AUTOSAR XML (schema 00046)
package /ComponentTypes
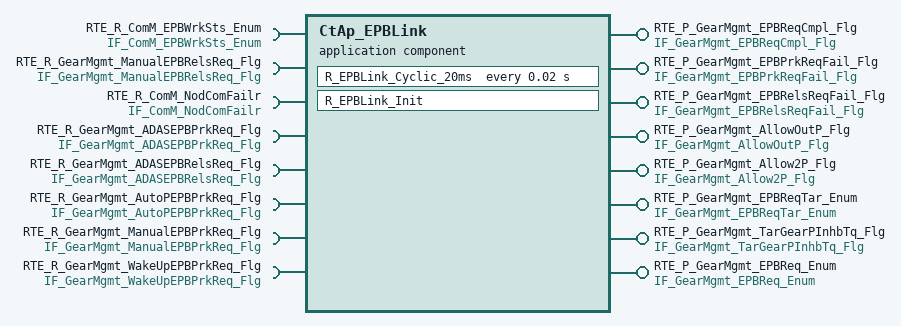
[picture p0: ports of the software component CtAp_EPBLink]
  application sw component type CtAp_EPBLink
    8 x require port:
      RTE_R_ComM_EPBWrkSts_Enum: nonqueued-receiver-com-spec{data-element=tec_ComM_EPBWrkSts_Enum, filter=data-filter-type=ALWAYS, init-value=0}, required-interface=IF_ComM_EPBWrkSts_Enum
      RTE_R_GearMgmt_ManualEPBRelsReq_Flg: nonqueued-receiver-com-spec{data-element=tec_GearMgmt_ManualEPBRelsReq_Flg, filter=data-filter-type=ALWAYS, init-value=0}, required-interface=IF_GearMgmt_ManualEPBRelsReq_Flg
      RTE_R_ComM_NodComFailr: required-interface=IF_ComM_NodComFailr
        required-com-specs:
          data-element=tec_ComM_ACUNodComFailr_Flg, filter=data-filter-type=ALWAYS, init-value=0
          data-element=tec_ComM_SGWNodComFailr_Flg, filter=data-filter-type=ALWAYS, init-value=0
          data-element=tec_ComM_CGWNodComFailr_Flg, filter=data-filter-type=ALWAYS, init-value=0
          data-element=tec_ComM_TCUNodComFailr_Flg, filter=data-filter-type=ALWAYS, init-value=0
          data-element=tec_ComM_BCMNodComFailr_Flg, filter=data-filter-type=ALWAYS, init-value=0
          data-element=tec_ComM_PRNDNodComFailr_Flg, filter=data-filter-type=ALWAYS, init-value=0
          data-element=tec_ComM_IVINodComFailr_Flg, filter=data-filter-type=ALWAYS, init-value=0
          data-element=tec_ComM_DCDCNodComFailr_Flg, filter=data-filter-type=ALWAYS, init-value=0
          data-element=tec_ComM_OBCNodComFailr_Flg, filter=data-filter-type=ALWAYS, init-value=0
          data-element=tec_ComM_CHIBSNodComFailr_Flg, filter=data-filter-type=ALWAYS, init-value=0
          data-element=tec_ComM_MCUNodComFailr_Flg, filter=data-filter-type=ALWAYS, init-value=0
          data-element=tec_ComM_EVCOMNodComFailr_Flg, filter=data-filter-type=ALWAYS, init-value=0
          data-element=tec_ComM_EPTIBSNodComFailr_Flg, filter=data-filter-type=ALWAYS, init-value=0
          data-element=tec_ComM_DCMNodComFailr_Flg, filter=data-filter-type=ALWAYS, init-value=0
          data-element=tec_ComM_BMSNodComFailr_Flg, filter=data-filter-type=ALWAYS, init-value=0
          data-element=tec_ComM_APTCNodComFailr_Flg, filter=data-filter-type=ALWAYS, init-value=0
          data-element=tec_ComM_ADCUNodComFailr_Flg, filter=data-filter-type=ALWAYS, init-value=0
          data-element=tec_ComM_DCMRRNodComFailr_Flg, filter=data-filter-type=ALWAYS, init-value=0
          data-element=tec_ComM_DCMRLNodComFailr_Flg, filter=data-filter-type=ALWAYS, init-value=0
          data-element=tec_ComM_DCMFRNodComFailr_Flg, filter=data-filter-type=ALWAYS, init-value=0
          data-element=tec_ComM_DCMFLNodComFailr_Flg, filter=data-filter-type=ALWAYS, init-value=0
          data-element=tec_ComM_SGWCHNodComFailr_Flg, init-value=0
      RTE_R_GearMgmt_ADASEPBPrkReq_Flg: nonqueued-receiver-com-spec{data-element=tec_GearMgmt_ADASEPBPrkReq_Flg, filter=data-filter-type=ALWAYS, init-value=0}, required-interface=IF_GearMgmt_ADASEPBPrkReq_Flg
      RTE_R_GearMgmt_ADASEPBRelsReq_Flg: nonqueued-receiver-com-spec{data-element=tec_GearMgmt_ADASEPBRelsReq_Flg, filter=data-filter-type=ALWAYS, init-value=0}, required-interface=IF_GearMgmt_ADASEPBRelsReq_Flg
      RTE_R_GearMgmt_AutoPEPBPrkReq_Flg: nonqueued-receiver-com-spec{data-element=tec_GearMgmt_AutoPEPBPrkReq_Flg, filter=data-filter-type=ALWAYS, init-value=0}, required-interface=IF_GearMgmt_AutoPEPBPrkReq_Flg
      RTE_R_GearMgmt_ManualEPBPrkReq_Flg: nonqueued-receiver-com-spec{data-element=tec_GearMgmt_ManualEPBPrkReq_Flg, filter=data-filter-type=ALWAYS, init-value=0}, required-interface=IF_GearMgmt_ManualEPBPrkReq_Flg
      RTE_R_GearMgmt_WakeUpEPBPrkReq_Flg: nonqueued-receiver-com-spec{data-element=tec_GearMgmt_WakeUpEPBPrkReq_Flg, filter=data-filter-type=ALWAYS, init-value=0}, required-interface=IF_GearMgmt_WakeUpEPBPrkReq_Flg
    8 x provide port:
      RTE_P_GearMgmt_EPBReqCmpl_Flg: nonqueued-sender-com-spec{data-element=tec_GearMgmt_EPBReqCmpl_Flg, init-value=0}, provided-interface=IF_GearMgmt_EPBReqCmpl_Flg
      RTE_P_GearMgmt_EPBPrkReqFail_Flg: nonqueued-sender-com-spec{data-element=tec_GearMgmt_EPBPrkReqFail_Flg, init-value=0}, provided-interface=IF_GearMgmt_EPBPrkReqFail_Flg
      RTE_P_GearMgmt_EPBRelsReqFail_Flg: nonqueued-sender-com-spec{data-element=tec_GearMgmt_EPBRelsReqFail_Flg, init-value=0}, provided-interface=IF_GearMgmt_EPBRelsReqFail_Flg
      RTE_P_GearMgmt_AllowOutP_Flg: nonqueued-sender-com-spec{data-element=tec_GearMgmt_AllowOutP_Flg, init-value=0}, provided-interface=IF_GearMgmt_AllowOutP_Flg
      RTE_P_GearMgmt_Allow2P_Flg: nonqueued-sender-com-spec{data-element=tec_GearMgmt_Allow2P_Flg, init-value=0}, provided-interface=IF_GearMgmt_Allow2P_Flg
      RTE_P_GearMgmt_EPBReqTar_Enum: nonqueued-sender-com-spec{data-element=tec_GearMgmt_EPBReqTar_Enum, init-value=0}, provided-interface=IF_GearMgmt_EPBReqTar_Enum
      RTE_P_GearMgmt_TarGearPInhbTq_Flg: nonqueued-sender-com-spec{data-element=tec_GearMgmt_TarGearPInhbTq_Flg, init-value=0}, provided-interface=IF_GearMgmt_TarGearPInhbTq_Flg
      RTE_P_GearMgmt_EPBReq_Enum: nonqueued-sender-com-spec{data-element=tec_GearMgmt_EPBReq_Enum, init-value=0}, provided-interface=IF_GearMgmt_EPBReq_Enum
    behavior CtAp_EPBLink_InternalBehavior
      timing event TMT_R_EPBLink_Cyclic_20ms: start-on-event=R_EPBLink_Cyclic_20ms, period=0.02
      init event CtAp_EPBLink_InitEvent: start-on-event=R_EPBLink_Init
      runnable R_EPBLink_Cyclic_20ms
        data-receive-point-by-arguments:
          8 x access:
            REC_RTE_R_ComM_EPBWrkSts_Enum_tec_ComM_EPBWrkSts_Enum: accessed-variable=RTE_R_ComM_EPBWrkSts_Enum.tec_ComM_EPBWrkSts_Enum
            REC_RTE_R_ComM_NodComFailr_tec_ComM_CHIBSNodComFailr_Flg: accessed-variable=RTE_R_ComM_NodComFailr.tec_ComM_CHIBSNodComFailr_Flg
            REC_RTE_R_GearMgmt_ADASEPBPrkReq_Flg_tec_GearMgmt_ADASEPBPrkReq_Flg: accessed-variable=RTE_R_GearMgmt_ADASEPBPrkReq_Flg.tec_GearMgmt_ADASEPBPrkReq_Flg
            REC_RTE_R_GearMgmt_ADASEPBRelsReq_Flg_tec_GearMgmt_ADASEPBRelsReq_Flg: accessed-variable=RTE_R_GearMgmt_ADASEPBRelsReq_Flg.tec_GearMgmt_ADASEPBRelsReq_Flg
            REC_RTE_R_GearMgmt_AutoPEPBPrkReq_Flg_tec_GearMgmt_AutoPEPBPrkReq_Flg: accessed-variable=RTE_R_GearMgmt_AutoPEPBPrkReq_Flg.tec_GearMgmt_AutoPEPBPrkReq_Flg
            REC_RTE_R_GearMgmt_ManualEPBPrkReq_Flg_tec_GearMgmt_ManualEPBPrkReq_Flg: accessed-variable=RTE_R_GearMgmt_ManualEPBPrkReq_Flg.tec_GearMgmt_ManualEPBPrkReq_Flg
            REC_RTE_R_GearMgmt_ManualEPBRelsReq_Flg_tec_GearMgmt_ManualEPBRelsReq_Flg: accessed-variable=RTE_R_GearMgmt_ManualEPBRelsReq_Flg.tec_GearMgmt_ManualEPBRelsReq_Flg
            REC_RTE_R_GearMgmt_WakeUpEPBPrkReq_Flg_tec_GearMgmt_WakeUpEPBPrkReq_Flg: accessed-variable=RTE_R_GearMgmt_WakeUpEPBPrkReq_Flg.tec_GearMgmt_WakeUpEPBPrkReq_Flg
        data-send-points:
          8 x access:
            SEND_RTE_P_GearMgmt_Allow2P_Flg_tec_GearMgmt_Allow2P_Flg: accessed-variable=RTE_P_GearMgmt_Allow2P_Flg.tec_GearMgmt_Allow2P_Flg
            SEND_RTE_P_GearMgmt_AllowOutP_Flg_tec_GearMgmt_AllowOutP_Flg: accessed-variable=RTE_P_GearMgmt_AllowOutP_Flg.tec_GearMgmt_AllowOutP_Flg
            SEND_RTE_P_GearMgmt_EPBPrkReqFail_Flg_tec_GearMgmt_EPBPrkReqFail_Flg: accessed-variable=RTE_P_GearMgmt_EPBPrkReqFail_Flg.tec_GearMgmt_EPBPrkReqFail_Flg
            SEND_RTE_P_GearMgmt_EPBRelsReqFail_Flg_tec_GearMgmt_EPBRelsReqFail_Flg: accessed-variable=RTE_P_GearMgmt_EPBRelsReqFail_Flg.tec_GearMgmt_EPBRelsReqFail_Flg
            SEND_RTE_P_GearMgmt_EPBReqCmpl_Flg_tec_GearMgmt_EPBReqCmpl_Flg: accessed-variable=RTE_P_GearMgmt_EPBReqCmpl_Flg.tec_GearMgmt_EPBReqCmpl_Flg
            SEND_RTE_P_GearMgmt_EPBReqTar_Enum_tec_GearMgmt_EPBReqTar_Enum: accessed-variable=RTE_P_GearMgmt_EPBReqTar_Enum.tec_GearMgmt_EPBReqTar_Enum
            SEND_RTE_P_GearMgmt_EPBReq_Enum_tec_GearMgmt_EPBReq_Enum: accessed-variable=RTE_P_GearMgmt_EPBReq_Enum.tec_GearMgmt_EPBReq_Enum
            SEND_RTE_P_GearMgmt_TarGearPInhbTq_Flg_tec_GearMgmt_TarGearPInhbTq_Flg: accessed-variable=RTE_P_GearMgmt_TarGearPInhbTq_Flg.tec_GearMgmt_TarGearPInhbTq_Flg
      runnable R_EPBLink_Init
  swc implementation CtAp_EPBLink_Implementation: behavior=CtAp_EPBLink_InternalBehavior
